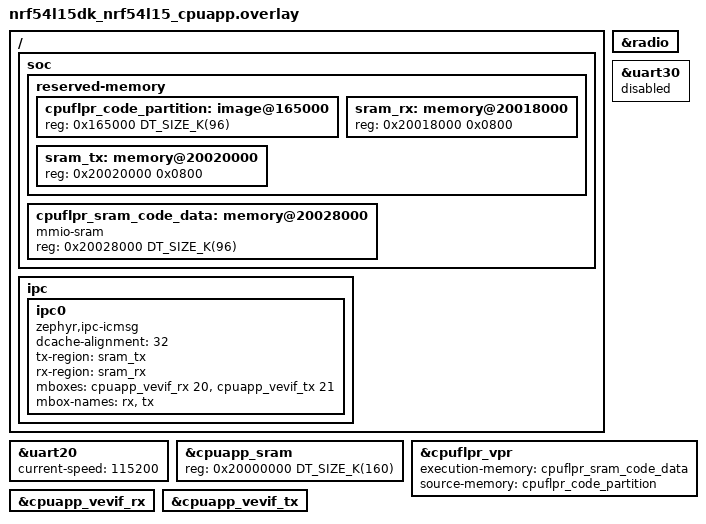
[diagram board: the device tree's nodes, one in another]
/* Device tree overlay for nRF54L15 dual-core application */

&radio {
	status = "okay";
};

&uart20 {
	status = "okay";
	current-speed = <115200>;
};

&uart30 {
	status = "reserved";
};

/* Resize cpuapp_sram to make room for FLPR */
&cpuapp_sram {
	reg = <0x20000000 DT_SIZE_K(160)>;
	ranges = <0x0 0x20000000 0x28000>;
};

/ {
	soc {
		reserved-memory {
			#address-cells = <1>;
			#size-cells = <1>;

			/* FLPR core code partition */
			cpuflpr_code_partition: image@165000 {
				reg = <0x165000 DT_SIZE_K(96)>;
			};

			/* IPC shared memory */
			sram_rx: memory@20018000 {
				reg = <0x20018000 0x0800>;
			};

			sram_tx: memory@20020000 {
				reg = <0x20020000 0x0800>;
			};
		};

		/* FLPR SRAM for code and data */
		cpuflpr_sram_code_data: memory@20028000 {
			compatible = "mmio-sram";
			reg = <0x20028000 DT_SIZE_K(96)>;
			#address-cells = <1>;
			#size-cells = <1>;
			ranges = <0x0 0x20028000 0x18000>;
		};
	};

	ipc {
		ipc0: ipc0 {
			compatible = "zephyr,ipc-icmsg";
			dcache-alignment = <32>;
			tx-region = <&sram_tx>;
			rx-region = <&sram_rx>;
			mboxes = <&cpuapp_vevif_rx 20>, <&cpuapp_vevif_tx 21>;
			mbox-names = "rx", "tx";
			status = "okay";
		};
	};
};

/* IPC configuration for inter-core communication */
&cpuflpr_vpr {
	status = "okay";
	execution-memory = <&cpuflpr_sram_code_data>;
	source-memory = <&cpuflpr_code_partition>;
};

&cpuapp_vevif_rx {
	status = "okay";
};

&cpuapp_vevif_tx {
	status = "okay";
};
